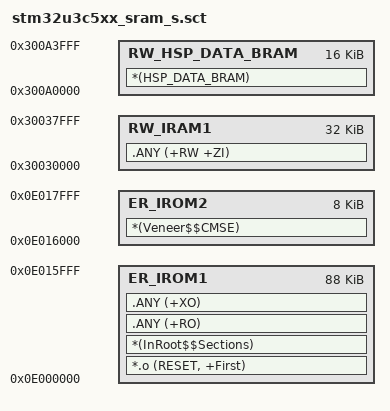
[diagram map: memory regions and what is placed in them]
; *************************************************************
; *** Scatter-Loading Description File generated by uVision ***
; *************************************************************

LR_IROM1 0x0E000000 0x00016000  {    ; load region size_region
  ER_IROM1 0x0E000000 0x00016000  {  ; load address = execution address
    *.o (RESET, +First)
    *(InRoot$$Sections)
    .ANY (+RO)
    .ANY (+XO)
  }

  RW_IRAM1 0x30030000 0x00008000  {  ; RW data
    .ANY (+RW +ZI)
  }

  RW_HSP_DATA_BRAM  0x300A0000 0x4000  {
    *(HSP_DATA_BRAM)
  }
}

LR_IROM2 0x0E016000 0x00002000  {    ; load region size_region
  ER_IROM2 0x0E016000 0x00002000  {  ; load address = execution address
    *(Veneer$$CMSE)                  ; check with partition.h
  }
}
